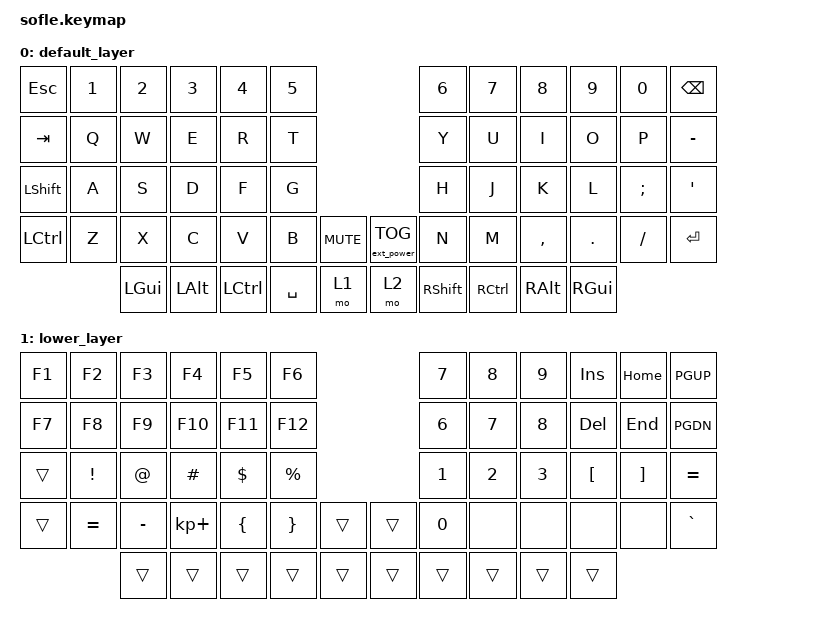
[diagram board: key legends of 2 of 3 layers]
/*
 * Copyright (c) 2020 The ZMK Contributors
 *
 * SPDX-License-Identifier: MIT
 */

#include <behaviors.dtsi>
#include <dt-bindings/zmk/keys.h>
#include <dt-bindings/zmk/bt.h>
#include <dt-bindings/zmk/ext_power.h>
#include <dt-bindings/zmk/rgb.h>
#include <dt-bindings/zmk/outputs.h>

/*
 * Temporarily here because nice nano v2 spi is not defined on ZMK Yet
 * Source: https://github.com/zmkfirmware/zmk/blob/main/app/boards/shields/reviung41/boards/nice_nano.overlay
 * GitHub Issue: https://github.com/zmkfirmware/zmk/issues/885
 */

#include <dt-bindings/led/led.h>

&pinctrl {
    spi3_default: spi3_default {
        group1 {
            psels = <NRF_PSEL(SPIM_MOSI, 0, 8)>;
        };
    };

    spi3_sleep: spi3_sleep {
        group1 {
            psels = <NRF_PSEL(SPIM_MOSI, 0, 8)>;
            low-power-enable;
        };
    };
};

&spi3 {
    compatible = "nordic,nrf-spim";
    status = "okay";

    pinctrl-0 = <&spi3_default>;
    pinctrl-1 = <&spi3_sleep>;
    pinctrl-names = "default", "sleep";

    led_strip: ws2812@0 {
        compatible = "worldsemi,ws2812-spi";
        label = "WS2812";

        /* SPI */
        reg = <0>; /* ignored, but necessary for SPI bindings */
        spi-max-frequency = <4000000>;

        /* WS2812 */
        chain-length = <30>;
        spi-one-frame = <0x70>;
        spi-zero-frame = <0x40>;

        color-mapping = <LED_COLOR_ID_GREEN LED_COLOR_ID_RED LED_COLOR_ID_BLUE>;
    };
};

/ {
    chosen {
        zmk,underglow = &led_strip;
    };
};

/* END temporary RGB support section */


/ {
    keymap {
        compatible = "zmk,keymap";

        default_layer {
// ------------------------------------------------------------------------------------------------------------------
// |  ESC   |  1  |  2  |  3   |  4   |  5   |                         |  6   |  7    |  8    |  9   |   0   | BKSPC |
// |  TAB   |  Q  |  W  |  E   |  R   |  T   |                         |  Y   |  U    |  I    |  O   |   P   |   -   |
// |  SHIFT |  A  |  S  |  D   |  F   |  G   |                         |  H   |  J    |  K    |  L   |   ;   |   '   |
// |  CTRL  |  Z  |  X  |  C   |  V   |  B   |  MUTE  |        | ExtPw |  N   |  M    |  ,    |  .   |   /   | ENTER |
//                | GUI | ALT  | CTRL | SPACE|  LOWER |        | RAISE | SHIFT| CTRL  | ALT   | GUI  |
            bindings = <
&kp ESC    &kp N1 &kp N2   &kp N3   &kp N4    &kp N5                                  &kp N6       &kp N7    &kp N8    &kp N9   &kp N0   &kp BSPC
&kp TAB    &kp Q  &kp W    &kp E    &kp R     &kp T                                   &kp Y        &kp U     &kp I     &kp O    &kp P    &kp MINUS
&kp LSHIFT &kp A  &kp S    &kp D    &kp F     &kp G                                   &kp H        &kp J     &kp K     &kp L    &kp SEMI &kp SQT
&kp LCTRL  &kp Z  &kp X    &kp C    &kp V     &kp B      &kp C_MUTE &ext_power EP_TOG &kp N        &kp M     &kp COMMA &kp DOT  &kp FSLH &kp ENTER
                  &kp LGUI &kp LALT &kp LCTRL &kp SPACE  &mo 1      &mo 2             &kp RSHIFT   &kp RCTRL &kp RALT  &kp RGUI
            >;

            sensor-bindings = <&inc_dec_kp C_VOL_UP C_VOL_DN &inc_dec_kp PG_UP PG_DN>;
        };

        lower_layer {
// TODO: Some binds are waiting for shifted keycode support.
// ------------------------------------------------------------------------------------------------------------
// |  F1   |  F2 |  F3 |  F4  |  F5  |   F6  |                    |  7   |   8   |   9   |  INS  |  HOME  |  PGUP   |
// |  F7   |  F8 |  F9 |  F10 |  F11 |   F12 |                    |  4   |   5   |   6   |  DEL  |  END   |  PGDN   |
// |       |  !  |  @  |  #   |  $   |  %    |                    |  1   |   2   |   3   |  [    |   ]    |   =     |
// |       |  =  |  -  |  +   |  {   |  }    |        |  |        |  0   |       |       |       |        |   GRAVE |
//               |     |      |      |       |        |  |        |      |       |       |       |
            bindings = <
&kp F1    &kp F2    &kp F3    &kp F4      &kp F5    &kp F6                    &kp N7    &kp N8   &kp N9     &kp INS    &kp HOME   &kp PGUP
&kp F7    &kp F8    &kp F9    &kp F10     &kp F11   &kp F12                   &kp N6    &kp N7   &kp N8     &kp DEL    &kp END    &kp PGDN
&trans    &kp EXCL  &kp AT    &kp HASH    &kp DLLR  &kp PRCNT                 &kp N1    &kp N2   &kp N3     &kp LBKT   &kp RBKT   &kp EQUAL
&trans    &kp EQUAL &kp MINUS &kp KP_PLUS &kp LBRC  &kp RBRC  &trans   &trans &kp N0    &none    &none      &none      &none      &kp GRAVE
                    &trans    &trans      &trans    &trans    &trans   &trans &trans   &trans     &trans    &trans
            >;

            sensor-bindings = <&inc_dec_kp C_VOL_UP C_VOL_DN &inc_dec_kp PG_UP PG_DN>;
        };

        raise_layer {
// ------------------------------------------------------------------------------------------------------------
// |BTCLR| BT1  | BT2  |  BT3  |  BT4  |  BT5 |                        |         |         |      |       |       | OUT_TOG  |
// |     | INS  | PSCR | GUI   |       |      |                        | PGUP    |         |   ^  |       |       |          |
// |     | ALT  | CTRL | SHIFT |       | CAPS |                        | PGDN    |   <-    |   v  |  ->   |  DEL  | BKSPC    |
// |     | UNDO | CUT  | COPY  | PASTE |      |      |       | RGB     | RGB_BRI | RGB_EFF |      |       |       |          |
//              |      |       |       |      |      |       |         | RGB_BRD | RGB_EFR |      |       |
            bindings = <
&bt BT_CLR &bt BT_SEL 0 &bt BT_SEL 1 &bt BT_SEL 2 &bt BT_SEL 3 &bt BT_SEL 4                              &trans              &trans             &trans   &trans    &trans  &out OUT_TOG
&trans     &kp INS      &kp PSCRN    &kp K_CMENU  &trans       &trans                                    &kp PG_UP           &trans             &kp UP   &trans    &kp N0  &trans
&trans     &kp LALT     &kp LCTRL    &kp LSHFT    &trans       &kp CLCK                                  &kp PG_DN           &kp LEFT           &kp DOWN &kp RIGHT &kp DEL &kp BSPC
&trans     &kp K_UNDO   &kp K_CUT    &kp K_COPY   &kp K_PASTE  &trans       &trans      &rgb_ug RGB_TOG  &rgb_ug RGB_BRI     &rgb_ug RGB_EFF    &trans   &trans    &trans  &trans
                        &trans       &trans       &trans       &trans       &trans      &trans           &rgb_ug RGB_BRD     &rgb_ug RGB_EFR    &trans
            >;

            sensor-bindings = <&inc_dec_kp C_VOL_UP C_VOL_DN &inc_dec_kp PG_UP PG_DN>;
        };
    };
};
